# cslr_timer register map
Vendor: Texas Instruments
Peripheral module from a debugger description file (folder C5517).
Address unit: 16 bits
Registers are 16-bit, read-write, reset 0xFFFF unless marked. A register's access mark holds for its fields unless they carry their own. Offsets are as the file gives them; lines under a group give offsets from that group; [hi:lo] are bit positions; {n}, {i} and the like mark numbered series; 'fields as' and 'values as' point back to an identical list; <NAME> marks a mode.

## TIM — The TIM controller is used to setup the internal timers. Each timer can be configured as a Watchdog or a General purpose timer.
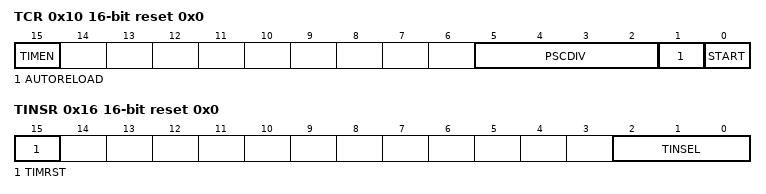
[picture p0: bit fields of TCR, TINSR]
0x10 TCR access not given reset 0x0 — Timer Control
  [15] TIMEN rw — Enables/disables the clocks for the counters to run. This starts both the Prescaler and the main counter.
    0=DISABLE (Timer counters are disabled); 1=ENABLE (Timer coutners are enabled and the prescaler and counter will begin to count down)
  [5:2] PSCDIV rw — Prescaler divider. The range are 0000 = divide by 2 to 1100 = divide by 8192 and 1101 = disable timer to 1111 = disable timer.
  [1] AUTORELOAD rw — automatically reloads the counter when it reaches 0
    0=DISABLE (Auto Reload is disabled); 1=ENABLE (Auto Reload is enabled)
  [0] START rw — When written to this bit loads and starts the counter. If the device is already in the process of counting down and a "1" is written to this bit the counter will be re-loaded with the start value and begin counting down again. When read the bit will be 1 when the counter is counting down this register will read 0 when the counter has stopped.
0x12 TIMPRD1 — Timer period LSW
  [15:0] PRD1 — The Timer period register is 32 bits wide. This is the LSW for the Timer period.
0x13 TIMPRD2 — Timer period MSW
  [15:0] PRD2 — The Timer period register is 32 bits wide. This is the MSW for the Timer period.
0x14 TIMCNT1 — Timer Counter LSW
  [15:0] TIM1 — The timer is 32bits wide. This is the LSW for the timer counter
0x15 TIMCNT2 — Timer Counter MSW
  [15:0] TIM2 — The timer is 32bits wide. This is the MSW for the timer counter
0x16 TINSR access not given reset 0x0 — Timer Input Selection Register
  [15] TIMRST rw — Drives the corresponding Timer X module reset signal low (asserted) or high (deasserted. 0 = reset deasserted, Timer X module out of reset 1 = reset asserted, Timer X module in reset.
    0=CLEAR (Timer counters are not reset); 1=SET (Timer coutners are reset)
  [2:0] TINSEL rw — Timer Clock Input Source Selection 000 = Timer x clock is driven by the System Clock (PLL output) 001 = Timer x clock is driven by GPIO0+x, S0+x 010 = Timer x clock is driven by GPIO6+x, S10+x 011 = Timer x clock is driven by GPIO12+x, PD[2+x] 100 = Timer x clock is driven by GPIO18+x, PD[8+x] 101 = Timer x clock is driven by GPIO24+x, A[18+x] 110 = Timer x clock is driven by USB Oscillator 111 = Timer x clock is driven by PLL input clock
    0=PLLOUT (Timer clock is driven by the System Clock (PLL output)); 1=GPIO0 (Timer x clock is driven by GPIO0+x, S0+x); 2=GPIO6 (Timer x clock is driven by GPIO6+x, S10+x); 3=GPIO12 (Timer x clock is driven by GPIO12+x, PD[2+x]); 4=GPIO18 (Timer x clock is driven by GPIO18+x, PD[8+x]); 5=GPIO24 (Timer x clock is driven by GPIO24+x, A[18+x]); 6=USBCLK (Timer x clock is driven by USB Oscillator); 7=PLLIN (Timer x clock is driven by PLL input clock)
